# iospear320 register map
Registers are 32-bit, access not given, no defined reset value unless marked. A register's access mark holds for its fields unless they carry their own. Addresses are absolute; registers are grouped by the start of their names; [hi:lo] are bit positions; {n}, {i} and the like mark numbered series; 'fields as' and 'values as' point back to an identical list.

## SMI
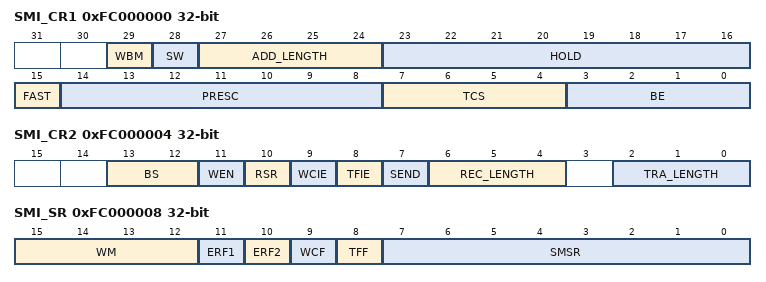
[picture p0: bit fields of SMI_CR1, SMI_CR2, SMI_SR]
0xFC000000 SMI_CR1
  [29] WBM, [28] SW, [27:24] ADD_LENGTH, [23:16] HOLD, [15] FAST, [14:8] PRESC, [7:4] TCS, [3:0] BE
0xFC000004 SMI_CR2
  [13:12] BS, [11] WEN, [10] RSR, [9] WCIE, [8] TFIE, [7] SEND, [6:4] REC_LENGTH, [2:0] TRA_LENGTH
0xFC000008 SMI_SR
  [15:12] WM, [11] ERF1, [10] ERF2, [9] WCF, [8] TFF, [7:0] SMSR
0xFC00000C SMI_TR
0xFC000010 SMI_RR

## TIMER0
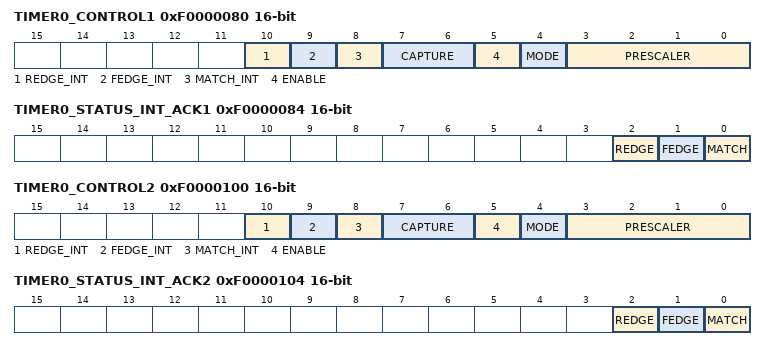
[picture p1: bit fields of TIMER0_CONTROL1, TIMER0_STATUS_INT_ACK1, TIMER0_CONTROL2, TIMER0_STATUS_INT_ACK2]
0xF0000080 TIMER0_CONTROL1 16-bit
  [10] REDGE_INT, [9] FEDGE_INT, [8] MATCH_INT, [7:6] CAPTURE, [5] ENABLE, [4] MODE, [3:0] PRESCALER
0xF0000084 TIMER0_STATUS_INT_ACK1 16-bit
  [2] REDGE, [1] FEDGE, [0] MATCH
0xF0000088 TIMER0_COMPARE1 16-bit
0xF000008C TIMER0_COUNT1 16-bit
0xF0000090 TIMER0_REDG_CAPT1 16-bit
0xF0000094 TIMER0_FEDG_CAPT1 16-bit
0xF0000100 TIMER0_CONTROL2 16-bit
  fields as TIMER0_CONTROL1
0xF0000104 TIMER0_STATUS_INT_ACK2 16-bit
  [2] REDGE, [1] FEDGE, [0] MATCH
0xF0000108 TIMER0_COMPARE2 16-bit
0xF000010C TIMER0_COUNT2 16-bit
0xF0000110 TIMER0_REDG_CAPT2 16-bit
0xF0000114 TIMER0_FEDG_CAPT2 16-bit

## TIMER1
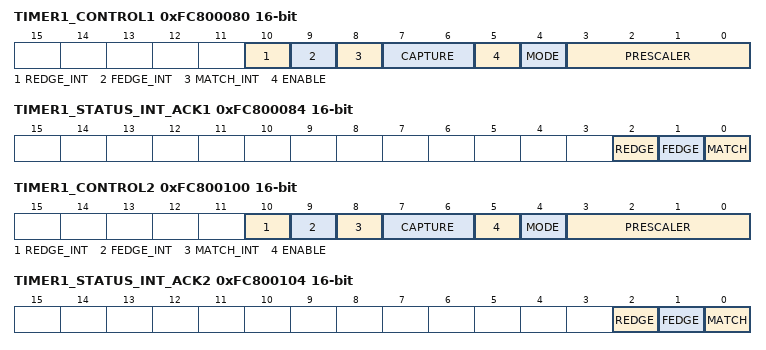
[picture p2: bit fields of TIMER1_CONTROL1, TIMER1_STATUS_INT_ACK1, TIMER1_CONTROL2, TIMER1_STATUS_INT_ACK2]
0xFC800080 TIMER1_CONTROL1 16-bit
  [10] REDGE_INT, [9] FEDGE_INT, [8] MATCH_INT, [7:6] CAPTURE, [5] ENABLE, [4] MODE, [3:0] PRESCALER
0xFC800084 TIMER1_STATUS_INT_ACK1 16-bit
  [2] REDGE, [1] FEDGE, [0] MATCH
0xFC800088 TIMER1_COMPARE1 16-bit
0xFC80008C TIMER1_COUNT1 16-bit
0xFC800090 TIMER1_REDG_CAPT1 16-bit
0xFC800094 TIMER1_FEDG_CAPT1 16-bit
0xFC800100 TIMER1_CONTROL2 16-bit
  fields as TIMER1_CONTROL1
0xFC800104 TIMER1_STATUS_INT_ACK2 16-bit
  [2] REDGE, [1] FEDGE, [0] MATCH
0xFC800108 TIMER1_COMPARE2 16-bit
0xFC80010C TIMER1_COUNT2 16-bit
0xFC800110 TIMER1_REDG_CAPT2 16-bit
0xFC800114 TIMER1_FEDG_CAPT2 16-bit

## TIMER2
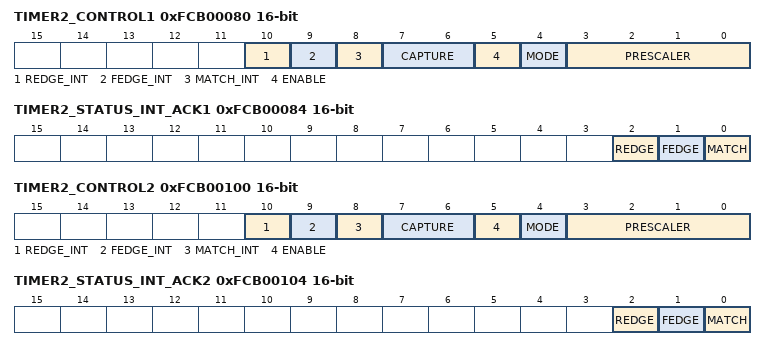
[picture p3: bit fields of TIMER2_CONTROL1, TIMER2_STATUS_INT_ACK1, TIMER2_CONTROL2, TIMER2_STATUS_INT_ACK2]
0xFCB00080 TIMER2_CONTROL1 16-bit
  [10] REDGE_INT, [9] FEDGE_INT, [8] MATCH_INT, [7:6] CAPTURE, [5] ENABLE, [4] MODE, [3:0] PRESCALER
0xFCB00084 TIMER2_STATUS_INT_ACK1 16-bit
  [2] REDGE, [1] FEDGE, [0] MATCH
0xFCB00088 TIMER2_COMPARE1 16-bit
0xFCB0008C TIMER2_COUNT1 16-bit
0xFCB00090 TIMER2_REDG_CAPT1 16-bit
0xFCB00094 TIMER2_FEDG_CAPT1 16-bit
0xFCB00100 TIMER2_CONTROL2 16-bit
  fields as TIMER2_CONTROL1
0xFCB00104 TIMER2_STATUS_INT_ACK2 16-bit
  [2] REDGE, [1] FEDGE, [0] MATCH
0xFCB00108 TIMER2_COMPARE2 16-bit
0xFCB0010C TIMER2_COUNT2 16-bit
0xFCB00110 TIMER2_REDG_CAPT2 16-bit
0xFCB00114 TIMER2_FEDG_CAPT2 16-bit

## tSCS
{0x40000000+0x18*i} tSCS_{i}_reg 16-bit (i=0..3)

## tSE
{0x40000004+0x18*i} tSE_{i}_reg 16-bit (i=0..3)

## tENw
{0x40000008+0x18*i} tENw_{i}_reg 16-bit (i=0..3)

## tENr
{0x4000000C+0x18*i} tENr_{i}_reg 16-bit (i=0..3)

## tDCS
{0x40000010+0x18*i} tDCS_{i}_reg 16-bit (i=0..3)

## control
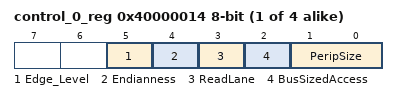
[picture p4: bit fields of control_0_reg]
{0x40000014+0x18*i} control_{i}_reg 8-bit (i=0..3)
  [5] Edge_Level, [4] Endianness, [3] ReadLane, [2] BusSizedAccess, [1:0] PeripSize

## Mmc
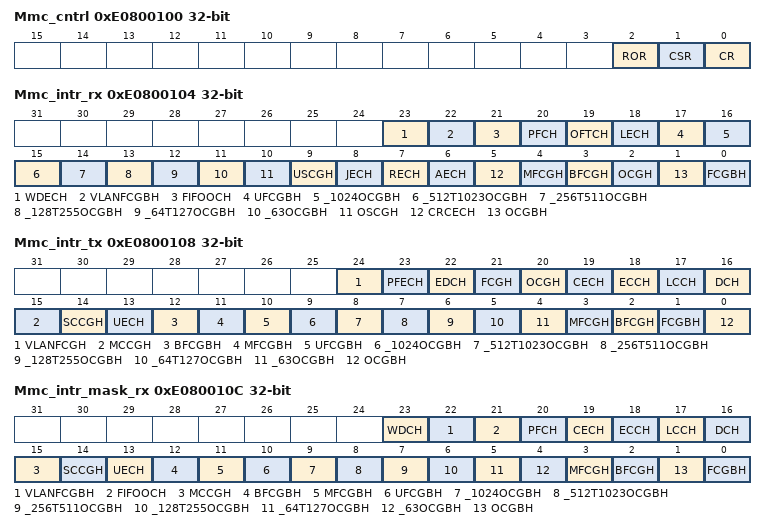
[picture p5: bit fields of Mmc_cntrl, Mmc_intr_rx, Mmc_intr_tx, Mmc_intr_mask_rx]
0xE0800100 Mmc_cntrl
  [2] ROR, [1] CSR, [0] CR
0xE0800104 Mmc_intr_rx
  [23] WDECH, [22] VLANFCGBH, [21] FIFOOCH, [20] PFCH, [19] OFTCH, [18] LECH, [17] UFCGBH, [16] _1024OCGBH, [15] _512T1023OCGBH, [14] _256T511OCGBH, [13] _128T255OCGBH, [12] _64T127OCGBH, [11] _63OCGBH, [10] OSCGH, [9] USCGH, [8] JECH, [7] RECH, [6] AECH, [5] CRCECH, [4] MFCGH, [3] BFCGH, [2] OCGH, [1] OCGBH, [0] FCGBH
0xE0800108 Mmc_intr_tx
  [24] VLANFCGH, [23] PFECH, [22] EDCH, [21] FCGH, [20] OCGH, [19] CECH, [18] ECCH, [17] LCCH, [16] DCH, [15] MCCGH, [14] SCCGH, [13] UECH, [12] BFCGBH, [11] MFCGBH, [10] UFCGBH, [9] _1024OCGBH, [8] _512T1023OCGBH, [7] _256T511OCGBH, [6] _128T255OCGBH, [5] _64T127OCGBH, [4] _63OCGBH, [3] MFCGH, [2] BFCGH, [1] FCGBH, [0] OCGBH
0xE080010C Mmc_intr_mask_rx
  [23] WDCH, [22] VLANFCGBH, [21] FIFOOCH, [20] PFCH, [19] CECH, [18] ECCH, [17] LCCH, [16] DCH, [15] MCCGH, [14] SCCGH, [13] UECH, [12] BFCGBH, [11] MFCGBH, [10] UFCGBH, [9] _1024OCGBH, [8] _512T1023OCGBH, [7] _256T511OCGBH, [6] _128T255OCGBH, [5] _64T127OCGBH, [4] _63OCGBH, [3] MFCGH, [2] BFCGH, [1] OCGBH, [0] FCGBH
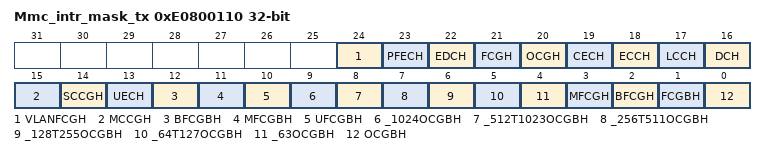
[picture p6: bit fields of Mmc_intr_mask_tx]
0xE0800110 Mmc_intr_mask_tx
  fields as Mmc_intr_tx
